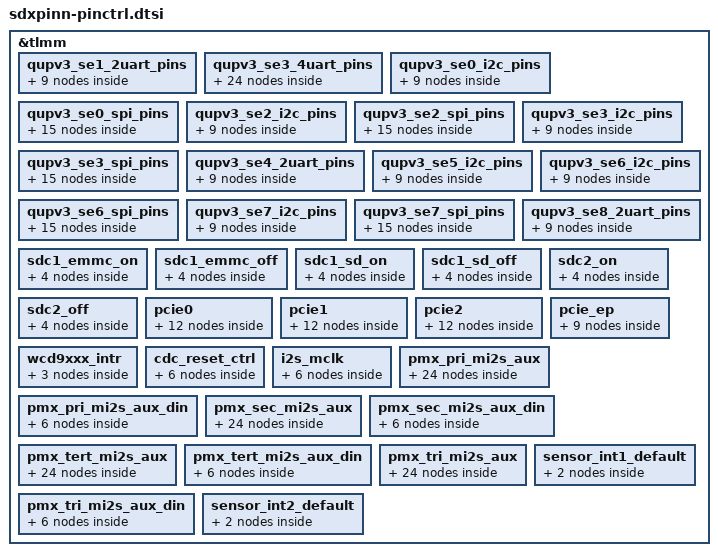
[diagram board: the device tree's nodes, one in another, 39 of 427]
&tlmm {
	qupv3_se1_2uart_pins: qupv3_se1_2uart_pins {
		qupv3_se1_2uart_tx_active: qupv3_se1_2uart_tx_active {
			mux {
				pins = "gpio12";
				function = "qup_se1_l2_mira";
			};

			config {
				pins = "gpio12";
				drive-strength= <2>;
				bias-disable;
			};
		};

		qupv3_se1_2uart_rx_active: qupv3_se1_2uart_rx_active {
			mux {
				pins = "gpio13";
				function = "qup_se1_l3_mira";
			};

			config {
				pins = "gpio13";
				drive-strength= <2>;
				bias-disable;
			};
		};

		qupv3_se1_2uart_sleep: qupv3_se1_2uart_sleep {
			mux {
				pins = "gpio12", "gpio13";
				function = "gpio";
			};

			config {
				pins = "gpio12", "gpio13";
				drive-strength = <2>;
				bias-pull-down;
			};
		};
	};

	qupv3_se3_4uart_pins: qupv3_se3_4uart_pins {
		qupv3_se3_default_cts: qupv3_se3_default_cts {
			mux {
				pins = "gpio52";
				function = "gpio";
			};

			config {
				pins = "gpio52";
				drive-strength = <2>;
				bias-disable;
			};
		};

		qupv3_se3_default_rts: qupv3_se3_default_rts {
			mux {
				pins = "gpio53";
				function = "gpio";
			};

			config {
				pins = "gpio53";
				drive-strength = <2>;
				bias-pull-down;
			};
		};

		qupv3_se3_default_tx: qupv3_se3_default_tx {
			mux {
				pins = "gpio54";
				function = "gpio";
			};

			config {
				pins = "gpio54";
				drive-strength = <2>;
				bias-pull-up;
			};
		};

		qupv3_se3_default_rx: qupv3_se3_default_rx {
			mux {
				pins = "gpio55";
				function = "gpio";
			};

			config {
				pins = "gpio55";
				drive-strength = <2>;
				bias-pull-down;
			};
		};

		qupv3_se3_cts: qupv3_se3_cts {
			mux {
				pins = "gpio52";
				function = "qup_se3_l0";
			};

			config {
				pins = "gpio52";
				drive-strength = <2>;
				bias-disable;
			};
		};

		qupv3_se3_rts: qupv3_se3_rts {
			mux {
				pins = "gpio53";
				function = "qup_se3_l1";
			};

			config {
				pins = "gpio53";
				drive-strength = <2>;
				bias-pull-down;
			};
		};

		qupv3_se3_tx: qupv3_se3_tx {
			mux {
				pins = "gpio54";
				function = "qup_se3_l2";
			};

			config {
				pins = "gpio54";
				drive-strength = <2>;
				bias-pull-up;
			};
		};

		qupv3_se3_rx: qupv3_se3_rx {
			mux {
				pins = "gpio55";
				function = "qup_se3_l3";
			};

			config {
				pins = "gpio55";
				drive-strength = <2>;
				bias-disable;
			};
		};
	};

	qupv3_se0_i2c_pins: qupv3_se0_i2c_pins {
		qupv3_se0_i2c_sda_active: qupv3_se0_i2c_sda_active {
			mux {
				pins = "gpio8";
				function = "qup_se0_l0";
			};

			config {
				pins = "gpio8";
				drive-strength = <2>;
				bias-pull-up;
			};
		};

		qupv3_se0_i2c_scl_active: qupv3_se0_i2c_scl_active {
			mux {
				pins = "gpio9";
				function = "qup_se0_l1";
			};

			config {
				pins = "gpio9";
				drive-strength = <2>;
				bias-pull-up;
			};
		};

		qupv3_se0_i2c_sleep: qupv3_se0_i2c_sleep {
			mux {
				pins = "gpio8", "gpio9";
				function = "gpio";
			};

			config {
				pins = "gpio8", "gpio9";
				drive-strength = <2>;
				bias-disable;
			};
		};
	};

	qupv3_se0_spi_pins: qupv3_se0_spi_pins {
		qupv3_se0_spi_miso_active: qupv3_se0_spi_miso_active {
			mux {
				pins = "gpio8";
				function = "qup_se0_l0";
			};

			config {
				pins = "gpio8";
				drive-strength = <6>;
				bias-pull-down;
			};
		};

		qupv3_se0_spi_mosi_active: qupv3_se0_spi_mosi_active {
			mux {
				pins = "gpio9";
				function = "qup_se0_l1";
			};

			config {
				pins = "gpio9";
				drive-strength = <6>;
				bias-pull-down;
			};
		};

		qupv3_se0_spi_clk_active: qupv3_se0_spi_clk_active {
			mux {
				pins = "gpio10";
				function = "qup_se0_l2";
			};

			config {
				pins = "gpio10";
				drive-strength = <6>;
				bias-pull-down;
			};
		};

		qupv3_se0_spi_cs_active: qupv3_se0_spi_cs_active {
			mux {
				pins = "gpio11";
				function = "qup_se0_l3";
			};

			config {
				pins = "gpio11";
				drive-strength = <6>;
				bias-pull-down;
			};
		};

		qupv3_se0_spi_sleep: qupv3_se0_spi_sleep {
			mux {
				pins = "gpio8", "gpio9",
					"gpio10", "gpio11";
				function = "gpio";
			};

			config {
				pins = "gpio8", "gpio9",
					"gpio10", "gpio11";
				drive-strength = <2>;
				bias-pull-down;
			};
		};
	};

	qupv3_se2_i2c_pins: qupv3_se2_i2c_pins {
		qupv3_se2_i2c_sda_active: qupv3_se2_i2c_sda_active {
			mux {
				pins = "gpio14";
				function = "qup_se2_l0";
			};

			config {
				pins = "gpio14";
				drive-strength = <2>;
				bias-pull-up;
			};
		};

		qupv3_se2_i2c_scl_active: qupv3_se2_i2c_scl_active {
			mux {
				pins = "gpio15";
				function = "qup_se2_l1";
			};

			config {
				pins = "gpio15";
				drive-strength = <2>;
				bias-pull-up;
			};
		};

		qupv3_se2_i2c_sleep: qupv3_se2_i2c_sleep {
			mux {
				pins = "gpio14", "gpio15";
				function = "gpio";
			};

			config {
				pins = "gpio14", "gpio15";
				drive-strength = <2>;
				bias-disable;
			};
		};
	};

	qupv3_se2_spi_pins: qupv3_se2_spi_pins {
		qupv3_se2_spi_miso_active: qupv3_se2_spi_miso_active {
			mux {
				pins = "gpio14";
				function = "qup_se2_l0";
			};

			config {
				pins = "gpio14";
				drive-strength = <6>;
				bias-pull-down;
			};
		};

		qupv3_se2_spi_mosi_active: qupv3_se2_spi_mosi_active {
			mux {
				pins = "gpio15";
				function = "qup_se2_l1";
			};

			config {
				pins = "gpio15";
				drive-strength = <6>;
				bias-pull-down;
			};
		};

		qupv3_se2_spi_clk_active: qupv3_se2_spi_clk_active {
			mux {
				pins = "gpio16";
				function = "qup_se2_l2";
			};

			config {
				pins = "gpio16";
				drive-strength = <6>;
				bias-pull-down;
			};
		};

		qupv3_se2_spi_cs_active: qupv3_se2_spi_cs_active {
			mux {
				pins = "gpio17";
				function = "qup_se2_l3";
			};

			config {
				pins = "gpio17";
				drive-strength = <6>;
				bias-pull-down;
			};
		};

		qupv3_se2_spi_sleep: qupv3_se2_spi_sleep {
			mux {
				pins = "gpio14", "gpio15",
					"gpio16", "gpio17";
				function = "gpio";
			};

			config {
				pins = "gpio14", "gpio15",
					"gpio16", "gpio17";
				drive-strength = <2>;
				bias-pull-down;
			};
		};
	};

	qupv3_se3_i2c_pins: qupv3_se3_i2c_pins {
		qupv3_se3_i2c_sda_active: qupv3_se3_i2c_sda_active {
			mux {
				pins = "gpio52";
				function = "qup_se3_l0";
			};

			config {
				pins = "gpio52";
				drive-strength = <2>;
				bias-pull-up;
			};
		};

		qupv3_se3_i2c_scl_active: qupv3_se3_i2c_scl_active {
			mux {
				pins = "gpio53";
				function = "qup_se3_l1";
			};

			config {
				pins = "gpio53";
				drive-strength = <2>;
				bias-pull-up;
			};
		};

		qupv3_se3_i2c_sleep: qupv3_se3_i2c_sleep {
			mux {
				pins = "gpio52", "gpio53";
				function = "gpio";
			};

			config {
				pins = "gpio52", "gpio53";
				drive-strength = <2>;
				bias-disable;
			};
		};
	};

	qupv3_se3_spi_pins: qupv3_se3_spi_pins {
		qupv3_se3_spi_miso_active: qupv3_se3_spi_miso_active {
			mux {
				pins = "gpio52";
				function = "qup_se3_l0";
			};

			config {
				pins = "gpio52";
				drive-strength = <6>;
				bias-pull-down;
			};
		};

		qupv3_se3_spi_mosi_active: qupv3_se3_spi_mosi_active {
			mux {
				pins = "gpio53";
				function = "qup_se3_l1";
			};

			config {
				pins = "gpio53";
				drive-strength = <6>;
				bias-pull-down;
			};
		};

		qupv3_se3_spi_clk_active: qupv3_se3_spi_clk_active {
			mux {
				pins = "gpio54";
				function = "qup_se3_l2";
			};

			config {
				pins = "gpio54";
				drive-strength = <6>;
				bias-pull-down;
			};
		};

		qupv3_se3_spi_cs_active: qupv3_se3_spi_cs_active {
			mux {
				pins = "gpio55";
				function = "qup_se3_l3";
			};

			config {
				pins = "gpio55";
				drive-strength = <6>;
				bias-pull-down;
			};
		};

		qupv3_se3_spi_sleep: qupv3_se3_spi_sleep {
			mux {
				pins = "gpio52", "gpio53",
					"gpio54", "gpio55";
				function = "gpio";
			};

			config {
				pins = "gpio52", "gpio53",
					"gpio54", "gpio55";
				drive-strength = <2>;
				bias-pull-down;
			};
		};
	};

	qupv3_se4_2uart_pins: qupv3_se4_2uart_pins {
		qupv3_se4_2uart_tx_active: qupv3_se4_2uart_tx_active {
			mux {
				pins = "gpio64";
				function = "qup_se4_l2";
			};

			config {
				pins = "gpio64";
				drive-strength = <2>;
				bias-disable;
			};
		};

		qupv3_se4_2uart_rx_active: qupv3_se4_2uart_rx_active {
			mux {
				pins = "gpio65";
				function = "qup_se4_l3";
			};

			config {
				pins = "gpio65";
				drive-strength = <2>;
				bias-disable;
			};
		};

		qupv3_se4_2uart_sleep: qupv3_se4_2uart_sleep {
			mux {
				pins = "gpio64", "gpio65";
				function = "gpio";
			};

			config {
				pins = "gpio64", "gpio65";
				drive-strength = <2>;
				bias-pull-down;
			};
		};
	};

	qupv3_se5_i2c_pins: qupv3_se5_i2c_pins {
		qupv3_se5_i2c_sda_active: qupv3_se5_i2c_sda_active {
			mux {
				pins = "gpio110";
				function = "qup_se5_l0";
			};

			config {
				pins = "gpio110";
				drive-strength = <2>;
				bias-pull-up;
			};
		};

		qupv3_se5_i2c_scl_active: qupv3_se5_i2c_scl_active {
			mux {
				pins = "gpio111";
				function = "qup_se5_l1";
			};

			config {
				pins = "gpio111";
				drive-strength = <2>;
				bias-pull-up;
			};
		};

		qupv3_se5_i2c_sleep: qupv3_se5_i2c_sleep {
			mux {
				pins = "gpio110", "gpio111";
				function = "gpio";
			};

			config {
				pins = "gpio110", "gpio111";
				drive-strength = <2>;
				bias-disable;
			};
		};
	};

	qupv3_se6_i2c_pins: qupv3_se6_i2c_pins {
		qupv3_se6_i2c_sda_active: qupv3_se6_i2c_sda_active {
			mux {
				pins = "gpio112";
				function = "qup_se6_l0";
			};

			config {
				pins = "gpio112";
				drive-strength = <2>;
				bias-pull-up;
			};
		};

		qupv3_se6_i2c_scl_active: qupv3_se6_i2c_scl_active {
			mux {
				pins = "gpio113";
				function = "qup_se6_l1";
			};

			config {
				pins = "gpio113";
				drive-strength = <2>;
				bias-pull-up;
			};
		};

		qupv3_se6_i2c_sleep: qupv3_se6_i2c_sleep {
			mux {
				pins = "gpio112", "gpio113";
				function = "gpio";
			};

			config {
				pins = "gpio112", "gpio113";
				drive-strength = <2>;
				bias-disable;
			};
		};
	};

	qupv3_se6_spi_pins: qupv3_se6_spi_pins {
		qupv3_se6_spi_miso_active: qupv3_se6_spi_miso_active {
			mux {
				pins = "gpio112";
				function = "qup_se6_l0";
			};

			config {
				pins = "gpio112";
				drive-strength = <6>;
				bias-pull-down;
			};
		};

		qupv3_se6_spi_mosi_active: qupv3_se6_spi_mosi_active {
			mux {
				pins = "gpio113";
				function = "qup_se6_l1";
			};

			config {
				pins = "gpio113";
				drive-strength = <6>;
				bias-pull-down;
			};
		};

		qupv3_se6_spi_clk_active: qupv3_se6_spi_clk_active {
			mux {
				pins = "gpio114";
				function = "qup_se6_l2";
			};

			config {
				pins = "gpio114";
				drive-strength = <6>;
				bias-pull-down;
			};
		};

		qupv3_se6_spi_cs_active: qupv3_se6_spi_cs_active {
			mux {
				pins = "gpio115";
				function = "qup_se6_l3";
			};

			config {
				pins = "gpio115";
				drive-strength = <6>;
				bias-pull-down;
			};
		};

		qupv3_se6_spi_sleep: qupv3_se6_spi_sleep {
			mux {
				pins = "gpio112", "gpio113",
					"gpio114", "gpio115";
				function = "gpio";
			};

			config {
				pins = "gpio112", "gpio113",
					"gpio114", "gpio115";
				drive-strength = <2>;
				bias-pull-down;
			};
		};
	};

	qupv3_se7_i2c_pins: qupv3_se7_i2c_pins {
		qupv3_se7_i2c_sda_active: qupv3_se7_i2c_sda_active {
			mux {
				pins = "gpio116";
				function = "qup_se7_l0";
			};

			config {
				pins = "gpio116";
				drive-strength = <2>;
				bias-pull-up;
			};
		};

		qupv3_se7_i2c_scl_active: qupv3_se7_i2c_scl_active {
			mux {
				pins = "gpio117";
				function = "qup_se7_l1";
			};

			config {
				pins = "gpio117";
				drive-strength = <2>;
				bias-pull-up;
			};
		};

		qupv3_se7_i2c_sleep: qupv3_se7_i2c_sleep {
			mux {
				pins = "gpio116", "gpio117";
				function = "gpio";
			};

			config {
				pins = "gpio116", "gpio117";
				drive-strength = <2>;
				bias-disable;
			};
		};
	};

	qupv3_se7_spi_pins: qupv3_se7_spi_pins {
		qupv3_se7_spi_miso_active: qupv3_se7_spi_miso_active {
			mux {
				pins = "gpio116";
				function = "qup_se7_l0";
			};

			config {
				pins = "gpio116";
				drive-strength = <6>;
				bias-pull-down;
			};
		};

		qupv3_se7_spi_mosi_active: qupv3_se7_spi_mosi_active {
			mux {
				pins = "gpio117";
				function = "qup_se7_l1";
			};

			config {
				pins = "gpio117";
				drive-strength = <6>;
				bias-pull-down;
			};
		};

		qupv3_se7_spi_clk_active: qupv3_se7_spi_clk_active {
			mux {
				pins = "gpio118";
				function = "qup_se7_l2";
			};

			config {
				pins = "gpio118";
				drive-strength = <6>;
				bias-pull-down;
			};
		};

		qupv3_se7_spi_cs_active: qupv3_se7_spi_cs_active {
			mux {
				pins = "gpio119";
				function = "qup_se7_l3";
			};

			config {
				pins = "gpio119";
				drive-strength = <6>;
				bias-pull-down;
			};
		};

		qupv3_se7_spi_sleep: qupv3_se7_spi_sleep {
			mux {
				pins = "gpio116", "gpio117",
					"gpio118", "gpio119";
				function = "gpio";
			};

			config {
				pins = "gpio116", "gpio117",
					"gpio118", "gpio119";
				drive-strength = <2>;
				bias-pull-down;
			};
		};
	};

	qupv3_se8_2uart_pins: qupv3_se8_2uart_pins {
		qupv3_se8_2uart_tx_active: qupv3_se8_2uart_tx_active {
			mux {
				pins = "gpio124";
				function = "qup_se8_l2";
			};

			config {
				pins = "gpio124";
				drive-strength = <2>;
				bias-disable;
			};
		};

		qupv3_se8_2uart_rx_active: qupv3_se8_2uart_rx_active {
			mux {
				pins = "gpio125";
				function = "qup_se8_l3";
			};

			config {
				pins = "gpio125";
				drive-strength = <2>;
				bias-disable;
			};
		};

		qupv3_se8_2uart_sleep: qupv3_se8_2uart_sleep {
			mux {
				pins = "gpio124", "gpio125";
				function = "gpio";
			};

			config {
				pins = "gpio124", "gpio125";
				drive-strength = <2>;
				bias-pull-down;
			};
		};
	};

	sdc1_emmc_on: sdc1_emmc_on {
		clk {
			pins = "sdc1_clk";
			bias-disable;
			drive-strength = <16>;
		};

		cmd {
			pins = "sdc1_cmd";
			bias-pull-up;
			drive-strength = <10>;
		};

		data {
			pins = "sdc1_data";
			bias-pull-up;
			drive-strength = <10>;
		};

		rclk {
			pins = "sdc1_rclk";
			bias-pull-down;
		};
	};

	sdc1_emmc_off: sdc1_emmc_off {
		clk {
			pins = "sdc1_clk";
			bias-disable;
			drive-strength = <2>;
		};

		cmd {
			pins = "sdc1_cmd";
			bias-pull-up;
			drive-strength = <2>;
		};

		data {
			pins = "sdc1_data";
			bias-pull-up;
			drive-strength = <2>;
		};

		rclk {
			pins = "sdc1_rclk";
			bias-pull-down;
		};
	};

	sdc1_sd_on: sdc1_sd_on {
		clk {
			pins = "sdc1_clk";
			bias-disable;
			drive-strength = <16>;
		};

		cmd {
			pins = "sdc1_cmd";
			bias-pull-up;
			drive-strength = <10>;
		};

		data {
			pins = "sdc1_data";
			bias-pull-up;
			drive-strength = <10>;
		};

		sd-cd {
			pins = "gpio103";
			bias-pull-up;
			drive-strength = <2>;
		};
	};

	sdc1_sd_off: sdc1_sd_off {
		clk {
			pins = "sdc1_clk";
			bias-disable;
			drive-strength = <2>;
		};

		cmd {
			pins = "sdc1_cmd";
			bias-pull-up;
			drive-strength = <2>;
		};

		data {
			pins = "sdc1_data";
			bias-pull-up;
			drive-strength = <2>;
		};

		sd-cd {
			pins = "gpio103";
			bias-pull-up;
			drive-strength = <2>;
		};
	};

	sdc2_on: sdc2_on {
		clk {
			pins = "sdc2_clk";
			bias-disable;
			drive-strength = <16>;
		};

		cmd {
			pins = "sdc2_cmd";
			bias-pull-up;
			drive-strength = <10>;
		};

		data {
			pins = "sdc2_data";
			bias-pull-up;
			drive-strength = <10>;
		};

		sd-cd {
			pins = "gpio103";
			bias-pull-up;
			drive-strength = <2>;
		};
	};

	sdc2_off: sdc2_off {
		clk {
			pins = "sdc2_clk";
			bias-disable;
			drive-strength = <2>;
		};

		cmd {
			pins = "sdc2_cmd";
			bias-pull-up;
			drive-strength = <2>;
		};

		data {
			pins = "sdc2_data";
			bias-pull-up;
			drive-strength = <2>;
		};

		sd-cd {
			pins = "gpio103";
			bias-pull-up;
			drive-strength = <2>;
		};
	};

	pcie0 {
		pcie0_perst_default: pcie0_perst_default {
			mux {
				pins = "gpio44";
				function = "gpio";
			};

			config {
				pins = "gpio44";
				drive-strength = <2>;
				bias-pull-down;
			};
		};

		pcie0_clkreq_default: pcie0_clkreq_default {
			mux {
				pins = "gpio43";
				function = "pcie0_clkreq_n";
			};

			config {
				pins = "gpio43";
				drive-strength = <2>;
				bias-pull-up;
			};
		};

		pcie0_wake_default: pcie0_wake_default {
			mux {
				pins = "gpio42";
				function = "gpio";
			};

			config {
				pins = "gpio42";
				drive-strength = <2>;
				bias-pull-up;
			};
		};

		pcie0_clkreq_sleep: pcie0_clkreq_sleep {
			mux {
				pins = "gpio43";
				function = "gpio";
			};

			config {
				pins = "gpio43";
				drive-strength = <2>;
				bias-pull-up;
			};
		};
	};

	pcie1 {
		pcie1_perst_default: pcie1_perst_default {
			mux {
				pins = "gpio125";
				function = "gpio";
			};

			config {
				pins = "gpio125";
				drive-strength = <2>;
				bias-pull-down;
			};
		};

		pcie1_clkreq_default: pcie1_clkreq_default {
			mux {
				pins = "gpio124";
				function = "pcie1_clkreq_n";
			};

			config {
				pins = "gpio124";
				drive-strength = <2>;
				bias-pull-up;
			};
		};

		pcie1_wake_default: pcie1_wake_default {
			mux {
				pins = "gpio123";
				function = "gpio";
			};

			config {
				pins = "gpio123";
				drive-strength = <2>;
				bias-pull-up;
			};
		};

		pcie1_clkreq_sleep: pcie1_clkreq_sleep {
			mux {
				pins = "gpio124";
				function = "gpio";
			};

			config {
				pins = "gpio124";
				drive-strength = <2>;
				bias-pull-up;
			};
		};
	};

	pcie2 {
		pcie2_perst_default: pcie2_perst_default {
			mux {
				pins = "gpio122";
				function = "gpio";
			};

			config {
				pins = "gpio122";
				drive-strength = <2>;
				bias-pull-down;
			};
		};

		pcie2_clkreq_default: pcie2_clkreq_default {
			mux {
				pins = "gpio121";
				function = "pcie2_clkreq_n";
			};

			config {
				pins = "gpio121";
				drive-strength = <2>;
				bias-pull-up;
			};
		};

		pcie2_wake_default: pcie2_wake_default {
			mux {
				pins = "gpio120";
				function = "gpio";
			};

			config {
				pins = "gpio120";
				drive-strength = <2>;
				bias-pull-up;
			};
		};

		pcie2_clkreq_sleep: pcie2_clkreq_sleep {
			mux {
				pins = "gpio121";
				function = "gpio";
			};

			config {
				pins = "gpio121";
				drive-strength = <2>;
				bias-pull-up;
			};
		};
	};

	pcie_ep {
		pcie_ep_clkreq_default: pcie_ep_clkreq_default {
			mux {
				pins = "gpio43";
				function = "pcie0_clkreq_n";
			};

			config {
				pins = "gpio43";
				drive-strength = <2>;
				bias-disable;
				input-enable;
			};
		};

		pcie_ep_perst_default: pcie_ep_perst_default {
		       mux {
			       pins = "gpio44";
			       function = "gpio";
		       };

		       config {
			       pins = "gpio44";
			       drive-strength = <2>;
			       bias-pull-down;
		       };
		};

		pcie_ep_wake_default: pcie_ep_wake_default {
		      mux {
			      pins = "gpio42";
			      function = "gpio";
		      };

		      config {
			      pins = "gpio42";
			      drive-strength = <2>;
			      bias-disable;
		      };
	      };
	};

	wcd9xxx_intr {
		wcd_intr_default: wcd_intr_default {
			mux {
				pins = "gpio75";
				function = "gpio";
			};

			config {
				pins = "gpio75";
				drive-strength = <2>; /* 2 mA */
				bias-pull-down; /* pull down */
				input-enable;
			};
		};
	};

	cdc_reset_ctrl {
		cdc_reset_sleep: cdc_reset_sleep {
			mux {
				pins = "gpio77";
				function = "gpio";
			};

			config {
				pins = "gpio77";
				drive-strength = <2>;
				bias-disable;
				output-low;
			};
		};

		cdc_reset_active:cdc_reset_active {
			mux {
				pins = "gpio77";
				function = "gpio";
			};

			config {
				pins = "gpio77";
				drive-strength = <8>;
				bias-pull-down;
				output-high;
			};
		};
	};

	i2s_mclk {
		i2s_mclk_sleep: i2s_mclk_sleep {
			mux {
				pins = "gpio74";
				function = "i2s_mclk";
			};

			config {
				pins = "gpio74";
				drive-strength = <2>;	/* 2 mA */
				bias-pull-down;		/* PULL DOWN */
			};
		};

		i2s_mclk_active: i2s_mclk_active {
			mux {
				pins = "gpio74";
				function = "i2s_mclk";
			};

			config {
				pins = "gpio74";
				drive-strength = <8>;	/* 8 mA */
				bias-disable;		/* NO PULL*/
				output-high;
			};
		};
	};

	pmx_pri_mi2s_aux {
		pri_ws_sleep: pri_ws_sleep {
			mux {
				pins = "gpio16";
				function = "gpio";
			};

			config {
				pins = "gpio16";
				drive-strength = <2>;	/* 2 mA */
				bias-pull-down;		/* PULL DOWN */
				input-enable;
			};
		};

		pri_sck_sleep: pri_sck_sleep {
			mux {
				pins = "gpio19";
				function = "gpio";
			};

			config {
				pins = "gpio19";
				drive-strength = <2>;	/* 2 mA */
				bias-pull-down;		/* PULL DOWN */
				input-enable;
			};
		};

		pri_dout_sleep: pri_dout_sleep {
			mux {
				pins = "gpio18";
				function = "gpio";
			};

			config {
				pins = "gpio18";
				drive-strength = <2>;	/* 2 mA */
				bias-pull-down;		/* PULL DOWN */
				input-enable;
			};
		};

		pri_ws_active_master: pri_ws_active_master {
			mux {
				pins = "gpio16";
				function = "pri_mi2s_ws";
			};

			config {
				pins = "gpio16";
				drive-strength = <8>;	/* 8 mA */
				bias-disable;		/* NO PULL*/
				output-high;
			};
		};

		pri_sck_active_master: pri_sck_active_master {
			mux {
				pins = "gpio19";
				function = "pri_mi2s_sck";
			};

			config {
				pins = "gpio19";
				drive-strength = <8>;	/* 8 mA */
				bias-disable;		/* NO PULL*/
				output-high;
			};
		};

		pri_ws_active_slave: pri_ws_active_slave {
			mux {
				pins = "gpio16";
				function = "pri_mi2s_ws";
			};

			config {
				pins = "gpio16";
				drive-strength = <8>;	/* 8 mA */
				bias-disable;		/* NO PULL*/
			};
		};

		pri_sck_active_slave: pri_sck_active_slave {
			mux {
				pins = "gpio19";
				function = "pri_mi2s_sck";
			};

			config {
				pins = "gpio19";
				drive-strength = <8>;	/* 8 mA */
				bias-disable;		/* NO PULL*/
			};
		};

		pri_dout_active: pri_dout_active {
			mux {
				pins = "gpio18";
				function = "pri_mi2s_data1";
			};

			config {
				pins = "gpio18";
				drive-strength = <8>;	/* 8 mA */
				bias-disable;		/* NO PULL*/
				output-high;
			};
		};
	};

	pmx_pri_mi2s_aux_din {
		pri_din_sleep: pri_din_sleep {
			mux {
				pins = "gpio17";
				function = "gpio";
			};

			config {
				pins = "gpio17";
				drive-strength = <2>;	/* 2 mA */
				bias-pull-down;		/* PULL DOWN */
				input-enable;
			};
		};

		pri_din_active: pri_din_active {
			mux {
				pins = "gpio17";
				function = "pri_mi2s_data0";
			};

			config {
				pins = "gpio17";
				drive-strength = <8>;	/* 8 mA */
				bias-disable;		/* NO PULL */
			};
		};
	};

	pmx_sec_mi2s_aux {
		sec_ws_sleep: sec_ws_sleep {
			mux {
				pins = "gpio20";
				function = "gpio";
			};

			config {
				pins = "gpio20";
				drive-strength = <2>;	/* 2 mA */
				bias-pull-down;		/* PULL DOWN */
				input-enable;
			};
		};

		sec_sck_sleep: sec_sck_sleep {
			mux {
				pins = "gpio23";
				function = "gpio";
			};

			config {
				pins = "gpio23";
				drive-strength = <2>;	/* 2 mA */
				bias-pull-down;		/* PULL DOWN */
				input-enable;
			};
		};

		sec_dout_sleep: sec_dout_sleep {
			mux {
				pins = "gpio22";
				function = "gpio";
			};

			config {
				pins = "gpio22";
				drive-strength = <2>;	/* 2 mA */
				bias-pull-down;		/* PULL DOWN */
				input-enable;
			};
		};

		sec_ws_active_master: sec_ws_active_master {
			mux {
				pins = "gpio20";
				function = "sec_mi2s_ws";
			};

			config {
				pins = "gpio20";
				drive-strength = <8>;	/* 8 mA */
				bias-disable;		/* NO PULL*/
				output-high;
			};
		};

		sec_sck_active_master: sec_sck_active_master {
			mux {
				pins = "gpio23";
				function = "sec_mi2s_sck";
			};

			config {
				pins = "gpio23";
				drive-strength = <8>;	/* 8 mA */
				bias-disable;		/* NO PULL*/
				output-high;
			};
		};

		sec_ws_active_slave: sec_ws_active_slave {
			mux {
				pins = "gpio20";
				function = "sec_mi2s_ws";
			};

			config {
				pins = "gpio20";
				drive-strength = <8>;	/* 8 mA */
				bias-disable;		/* NO PULL*/
			};
		};

		sec_sck_active_slave: sec_sck_active_slave {
			mux {
				pins = "gpio23";
				function = "sec_mi2s_sck";
			};

			config {
				pins = "gpio23";
				drive-strength = <8>;	/* 8 mA */
				bias-disable;		/* NO PULL*/
			};
		};

		sec_dout_active: sec_dout_active {
			mux {
				pins = "gpio22";
				function = "sec_mi2s_data1";
			};

			config {
				pins = "gpio22";
				drive-strength = <8>;	/* 8 mA */
				bias-disable;		/* NO PULL*/
				output-high;
			};
		};
	};

	pmx_sec_mi2s_aux_din {
		bt_edl_default: sec_din_sleep: sec_din_sleep {
			mux {
				pins = "gpio21";
				function = "gpio";
			};

			config {
				pins = "gpio21";
				drive-strength = <2>;	/* 2 mA */
				bias-disable;		/* NO PULL */
				input-enable;
			};
		};

		sec_din_active: sec_din_active {
			mux {
				pins = "gpio21";
				function = "sec_mi2s_data0";
			};

			config {
				pins = "gpio21";
				drive-strength = <8>;	/* 8 mA */
				bias-disable;		/* NO PULL */
			};
		};
	};

	pmx_tert_mi2s_aux {
		tert_ws_sleep: tert_ws_sleep {
			mux {
				pins = "gpio98";
				function = "gpio";
			};

			config {
				pins = "gpio98";
				drive-strength = <2>;	/* 2 mA */
				bias-pull-down;		/* PULL DOWN */
				input-enable;
			};
		};

		tert_sck_sleep: tert_sck_sleep {
			mux {
				pins = "gpio101";
				function = "gpio";
			};

			config {
				pins = "gpio101";
				drive-strength = <2>;	/* 2 mA */
				bias-pull-down;		/* PULL DOWN */
				input-enable;
			};
		};

		tert_dout_sleep: tert_dout_sleep {
			mux {
				pins = "gpio100";
				function = "gpio";
			};

			config {
				pins = "gpio100";
				drive-strength = <2>;	/* 2 mA */
				bias-pull-down;		/* PULL DOWN */
				input-enable;
			};
		};

		tert_ws_active_master: tert_ws_active_master {
			mux {
				pins = "gpio98";
				function = "tert_mi2s_ws";
			};

			config {
				pins = "gpio98";
				drive-strength = <8>;	/* 8 mA */
				bias-disable;		/* NO PULL*/
				output-high;
			};
		};

		tert_sck_active_master: tert_sck_active_master {
			mux {
				pins = "gpio101";
				function = "tert_mi2s";
			};

			config {
				pins = "gpio101";
				drive-strength = <8>;	/* 8 mA */
				bias-disable;		/* NO PULL*/
				output-high;
			};
		};

		tert_ws_active_slave: tert_ws_active_slave {
			mux {
				pins = "gpio98";
				function = "tert_mi2s_ws";
			};

			config {
				pins = "gpio98";
				drive-strength = <8>;	/* 8 mA */
				bias-disable;		/* NO PULL*/
			};
		};

		tert_sck_active_slave: tert_sck_active_slave {
			mux {
				pins = "gpio101";
				function = "tert_mi2s";
			};

			config {
				pins = "gpio101";
				drive-strength = <8>;	/* 8 mA */
				bias-disable;		/* NO PULL*/
			};
		};

		tert_dout_active: tert_dout_active {
			mux {
				pins = "gpio100";
				function = "tert_mi2s";
			};

			config {
				pins = "gpio100";
				drive-strength = <8>;	/* 8 mA */
				bias-disable;		/* NO PULL*/
				output-high;
			};
		};
	};

	pmx_tert_mi2s_aux_din {
		tert_din_sleep: tert_din_sleep {
			mux {
				pins = "gpio99";
				function = "gpio";
			};

			config {
				pins = "gpio99";
				drive-strength = <2>;	/* 2 mA */
				bias-pull-down;		/* PULL DOWN */
				input-enable;
			};
		};

		tert_din_active: tert_din_active {
			mux {
				pins = "gpio99";
				function = "tert_mi2s";
			};

			config {
				pins = "gpio99";
				drive-strength = <8>;	/* 8 mA */
				bias-disable;		/* NO PULL */
			};
		};
	};

	pmx_tri_mi2s_aux {
		tri_ws_sleep: tri_ws_sleep {
			mux {
				pins = "gpio98";
				function = "gpio";
			};

			config {
				pins = "gpio98";
				drive-strength = <2>;	/* 2 mA */
				bias-pull-down;		/* PULL DOWN */
				input-enable;
			};
		};

		tri_sck_sleep: tri_sck_sleep {
			mux {
				pins = "gpio101";
				function = "gpio";
			};

			config {
				pins = "gpio101";
				drive-strength = <2>;	/* 2 mA */
				bias-pull-down;		/* PULL DOWN */
				input-enable;
			};
		};

		tri_dout_sleep: tri_dout_sleep {
			mux {
				pins = "gpio100";
				function = "gpio";
			};

			config {
				pins = "gpio100";
				drive-strength = <2>;	/* 2 mA */
				bias-pull-down;		/* PULL DOWN */
				input-enable;
			};
		};

		tri_ws_active_master: tri_ws_active_master {
			mux {
				pins = "gpio98";
				function = "tri_mi2s_ws";
			};

			config {
				pins = "gpio98";
				drive-strength = <8>;	/* 8 mA */
				bias-disable;		/* NO PULL*/
				output-high;
			};
		};

		tri_sck_active_master: tri_sck_active_master {
			mux {
				pins = "gpio101";
				function = "tri_mi2s_sck";
			};

			config {
				pins = "gpio101";
				drive-strength = <8>;	/* 8 mA */
				bias-disable;		/* NO PULL*/
				output-high;
			};
		};

		tri_ws_active_slave: tri_ws_active_slave {
			mux {
				pins = "gpio98";
				function = "tri_mi2s_ws";
			};

			config {
				pins = "gpio98";
				drive-strength = <8>;	/* 8 mA */
				bias-disable;		/* NO PULL*/
			};
		};

		tri_sck_active_slave: tri_sck_active_slave {
			mux {
				pins = "gpio101";
				function = "tri_mi2s_sck";
			};

			config {
				pins = "gpio101";
				drive-strength = <8>;	/* 8 mA */
				bias-disable;		/* NO PULL*/
			};
		};

		tri_dout_active: tri_dout_active {
			mux {
				pins = "gpio100";
				function = "tri_mi2s_data1";
			};

			config {
				pins = "gpio100";
				drive-strength = <8>;	/* 8 mA */
				bias-disable;		/* NO PULL*/
				output-high;
			};
		};
	};

	pmx_tri_mi2s_aux_din {
		tri_din_sleep: tri_din_sleep {
			mux {
				pins = "gpio99";
				function = "gpio";
			};

			config {
				pins = "gpio99";
				drive-strength = <2>;	/* 2 mA */
				bias-pull-down;		/* PULL DOWN */
				input-enable;
			};
		};

		tri_din_active: tri_din_active {
			mux {
				pins = "gpio99";
				function = "tri_mi2s_data0";
			};

			config {
				pins = "gpio99";
				drive-strength = <8>;	/* 8 mA */
				bias-disable;		/* NO PULL */
			};
		};
	};

	sensor_int1_default: sensor_int1_default {
			mux {
				pins = "gpio108";
				function = "gpio";
			};

			config {
				pins = "gpio108";
				drive-strength = <16>; /* 16 mA */
				bias-pull-down; /* pull down */
			};
	};

	sensor_int2_default: sensor_int2_default {
			mux {
				pins = "gpio109";
				function = "gpio";
			};

			config {
				pins = "gpio109";
				drive-strength = <16>; /* 16 mA */
				bias-pull-down; /* pull down */
			};
	};
};
